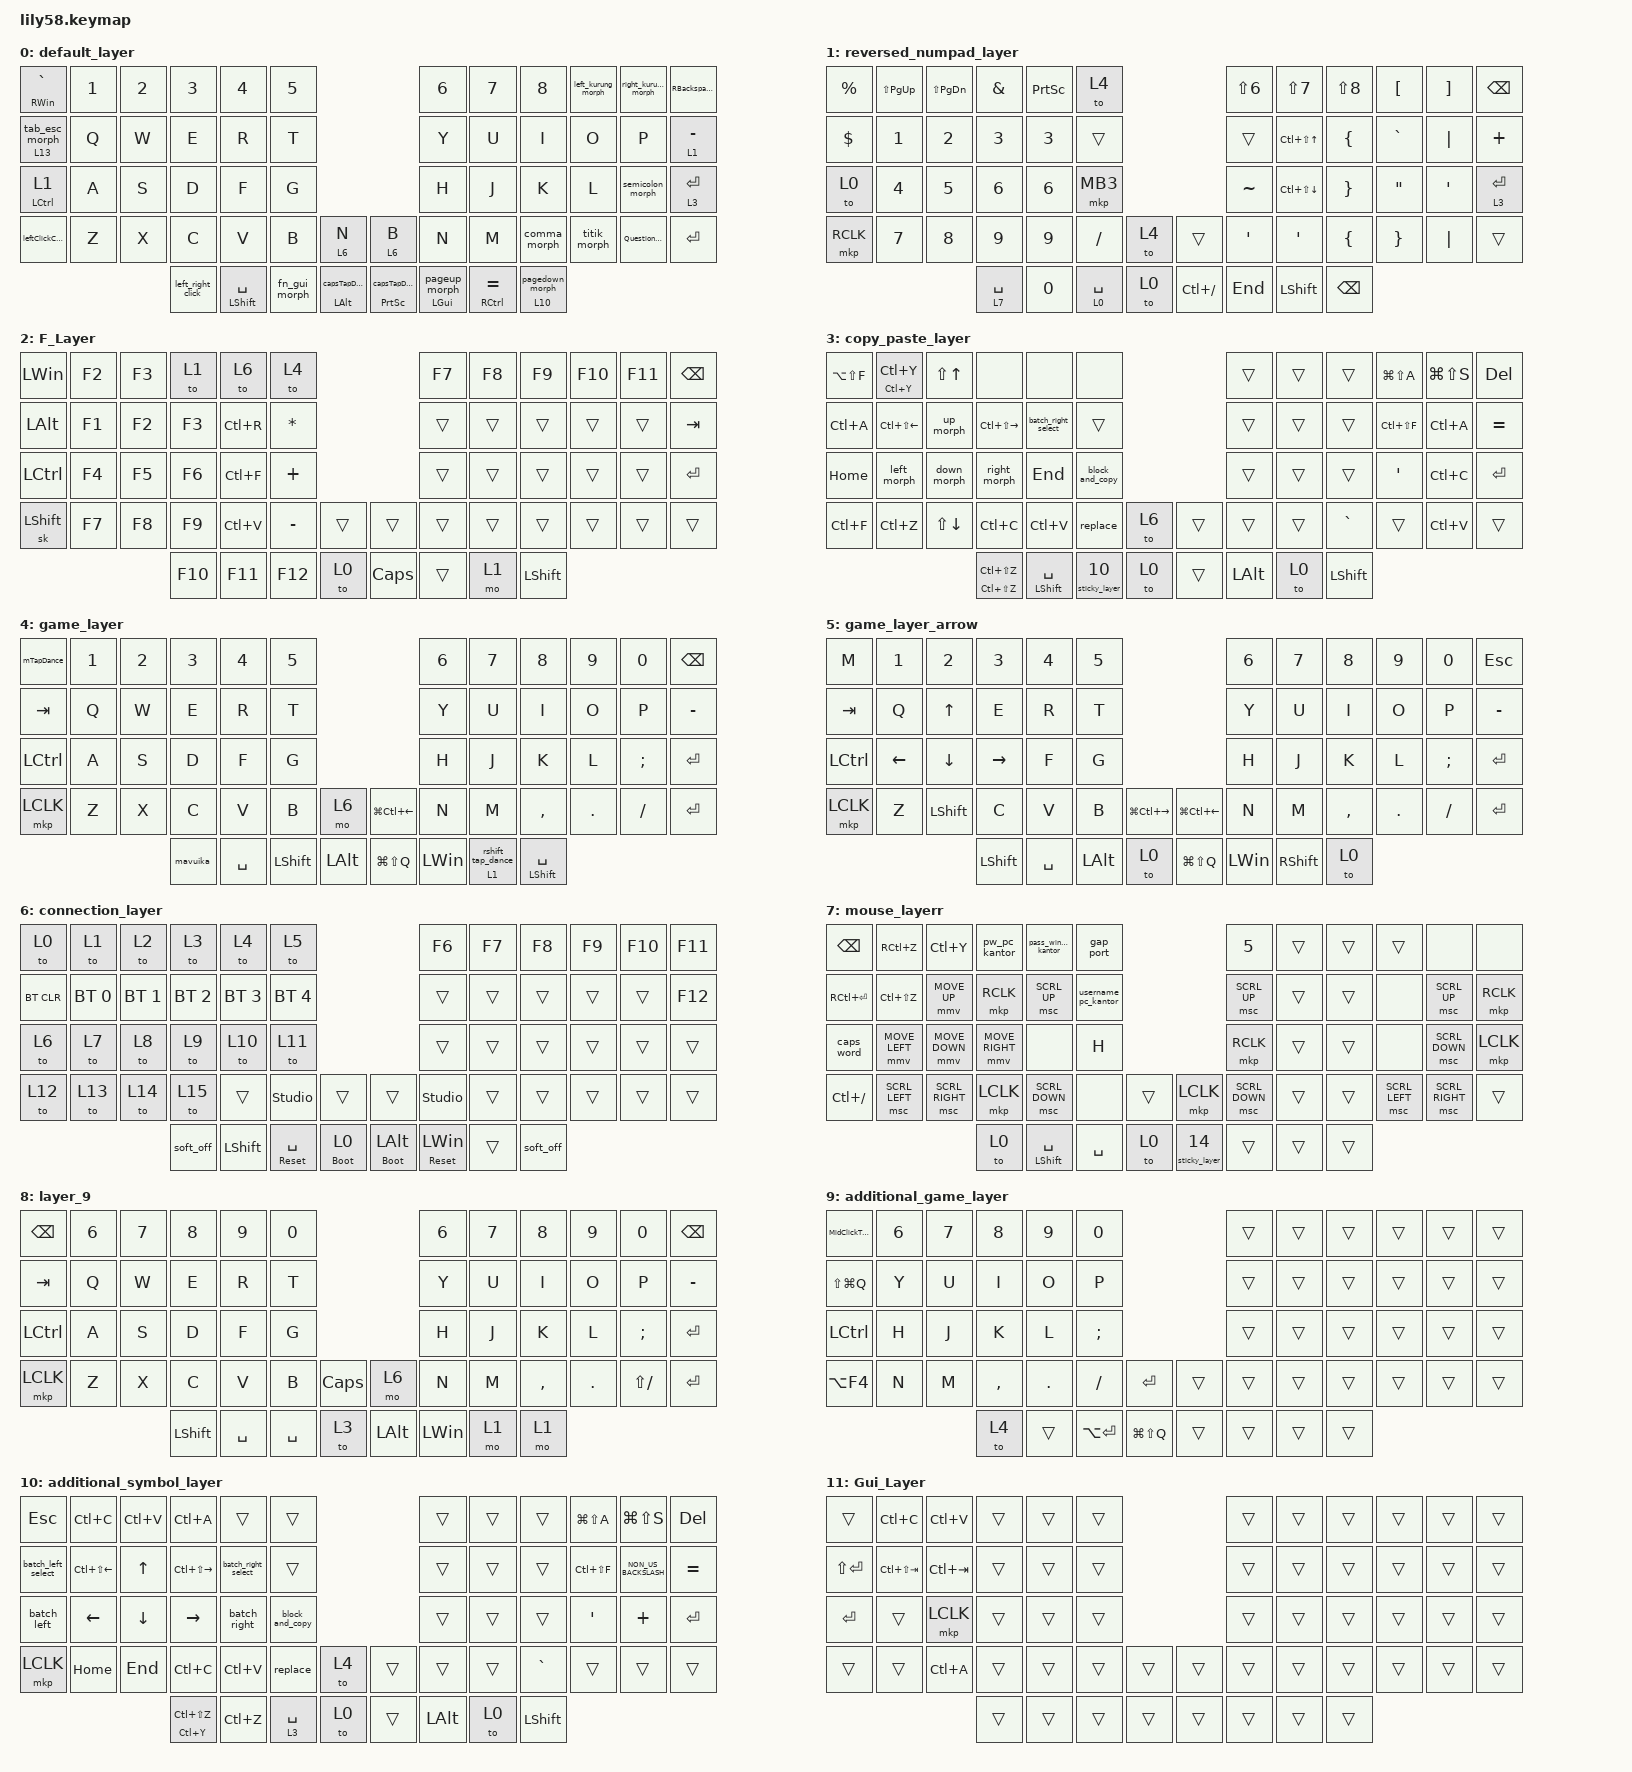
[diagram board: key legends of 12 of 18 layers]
/*
 * Copyright (c) 2020 The ZMK Contributors
 *
 * SPDX-License-Identifier: MIT
 */

#define SPLIT_USB_DETECT
#define ZMK_POINTING_DEFAULT_MOVE_VAL 1800  // default: 600
#define ZMK_POINTING_DEFAULT_SCRL_VAL 160    // default: 10

#include <dt-bindings/zmk/mouse.h>
#include <behaviors.dtsi>
#include <dt-bindings/zmk/bt.h>
#include <dt-bindings/zmk/keys.h>
#include <dt-bindings/zmk/pointing.h>

/ {
    combos {
        compatible = "zmk,combos";

        r_click {
            bindings = <&mkp RCLK>;
            key-positions = <37 25>;
            layers = <0>;
            timeout-ms = <1500>;
        };

        esc {
            bindings = <&kp ESCAPE>;
            key-positions = <13 37>;
            timeout-ms = <1500>;
            layers = <0>;
        };

        SPAM_W {
            bindings = <&kt W>;
            key-positions = <0 14>;
            layers = <4>;
        };

        win_game_mode {
            bindings = <&kp LEFT_WIN>;
            key-positions = <36 50>;
            layers = <5 4>;
        };

        click_copy {
            bindings = <&kp LC(C)>;
            key-positions = <50 14>;
            timeout-ms = <350>;
            layers = <0>;
        };

        click_paste {
            bindings = <&kp LC(V)>;
            key-positions = <50 27>;
            timeout-ms = <350>;
            layers = <0>;
        };

        click_select_all {
            bindings = <&kp LC(A)>;
            key-positions = <50 25>;
            timeout-ms = <350>;
            layers = <0>;
        };

        click_redo {
            bindings = <&kp LC(LS(Z))>;
            key-positions = <50 26>;
            layers = <0>;
            timeout-ms = <350>;
        };

        click_shift_enter {
            bindings = <&kp LS(ENTER)>;
            key-positions = <50 12>;
            layers = <0>;
            timeout-ms = <350>;
        };

        click_enter {
            bindings = <&kp ENTER>;
            key-positions = <50 39>;
            layers = <0>;
            timeout-ms = <350>;
        };

        click_ctrl_y {
            bindings = <&kp LC(Y)>;
            key-positions = <50 13>;
            timeout-ms = <350>;
            layers = <0>;
        };

        click_backspace {
            bindings = <&kp LC(BACKSPACE)>;
            key-positions = <50 0>;
            timeout-ms = <350>;
            layers = <0>;
        };

        click_delete {
            bindings = <&kp DELETE>;
            key-positions = <50 1>;
            layers = <0>;
            timeout-ms = <350>;
        };

        click_alt_tab {
            bindings = <&kp LA(TAB)>;
            key-positions = <50 38>;
            timeout-ms = <350>;
            layers = <0>;
        };

        click_undo {
            bindings = <&kp LC(Z)>;
            key-positions = <50 37>;
            timeout-ms = <350>;
            layers = <0>;
        };

        ctrl_delete {
            bindings = <&kp DELETE>;
            key-positions = <0 24>;
            timeout-ms = <350>;
            layers = <0>;
        };
    };

    macros {
        kurung: kurung {
            compatible = "zmk,behavior-macro";
            #binding-cells = <0>;
            bindings = <&kp LS(N9) &kp LS(N0)>;
            label = "KURUNG";
        };

        kurung2: kurung2 {
            compatible = "zmk,behavior-macro";
            #binding-cells = <0>;
            bindings = <&kp LS(LEFT_BRACKET) &kp LS(RIGHT_BRACKET)>;
            label = "KURUNG2";
        };

        kurung3: kurung3 {
            compatible = "zmk,behavior-macro";
            #binding-cells = <0>;
            bindings = <&kp LEFT_BRACKET &kp RIGHT_BRACKET>;
            label = "KURUNG3";
        };

        replace: replace {
            compatible = "zmk,behavior-macro";
            #binding-cells = <0>;
            bindings = <&mkp LCLK &mkp LCLK &kp LC(V)>;
            label = "REPLACE";
        };

        block_and_copy: block_and_copy {
            compatible = "zmk,behavior-macro";
            #binding-cells = <0>;
            bindings = <&mkp LCLK &mkp LCLK &kp LC(C)>;
            label = "BLOCK_AND_COPY";
        };

        sticky_shift_layer: sticky_shift_layer {
            compatible = "zmk,behavior-macro";
            #binding-cells = <0>;
            bindings = <&macro_tap>, <&none>;

            label = "STICKY_SHIFT_LAYER";
        };

        spam_f: spam_f {
            compatible = "zmk,behavior-macro";
            #binding-cells = <0>;
            bindings =
                <&kp F>,
                <&macro_wait_time 300>,
                <&kp F>,
                <&macro_wait_time 300>,
                <&kp F>,
                <&macro_wait_time 300>,
                <&kp F>,
                <&macro_wait_time 300>,
                <&kp F>,
                <&macro_wait_time 300>,
                <&kp F>,
                <&macro_wait_time 300>,
                <&kp F>,
                <&macro_wait_time 300>,
                <&kp F>,
                <&macro_wait_time 300>,
                <&kp F>,
                <&macro_wait_time 300>,
                <&kp F>,
                <&macro_wait_time 300>,
                <&kp F>,
                <&macro_wait_time 300>,
                <&kp F>,
                <&macro_wait_time 300>,
                <&kp F>,
                <&macro_wait_time 300>,
                <&kp F>,
                <&macro_wait_time 300>,
                <&kp F>,
                <&macro_wait_time 300>,
                <&kp F>,
                <&macro_wait_time 300>,
                <&kp F>;

            label = "SPAM_F";
        };

        username_pc_kantor: username_pc_kantor {
            compatible = "zmk,behavior-macro";
            #binding-cells = <0>;
            bindings = <&kp LS(A) &kp D &kp M &kp I &kp N &kp I &kp S &kp T &kp R &kp A &kp T &kp O &kp R>;
            label = "USERNAME_PC_KANTOR";
        };

        pw_pc_kantor: pw_pc_kantor {
            compatible = "zmk,behavior-macro";
            #binding-cells = <0>;
            bindings = <&none &kp G &kp N4 &kp P &kp DOT &kp LS(P) &kp N0 &kp N &kp C &kp N0 &kp LS(L) &kp AT &kp N1 &kp N3 &kp N7 &kp N4 &kp N0>;
            label = "PW_PC_KANTOR";
        };

        pass_windows_kantor: pass_windows_kantor {
            compatible = "zmk,behavior-macro";
            #binding-cells = <0>;
            bindings = <&none &kp LS(D) &kp N1 &kp LS(K) &kp N4 &kp DOT &kp N2 &kp N0 &kp N2 &kp N4>;
            label = "PASS_WINDOWS_KANTOR";
        };

        gap_port: gap_port {
            compatible = "zmk,behavior-macro";
            #binding-cells = <0>;
            bindings = <&none &kp G &kp A &kp P &kp P &kp R &kp I &kp N &kp T &kp AT &kp N2 &kp N0 &kp N2 &kp N1>;
            label = "GAP_PORT";
        };

        hold_scroll_up: hold_scroll_up {
            compatible = "zmk,behavior-macro";
            #binding-cells = <0>;
            bindings = <&macro_press>, <&msc SCRL_UP>;

            label = "HOLD_SCROLL_UP";
        };

        hold_scroll_down: hold_scroll_down {
            compatible = "zmk,behavior-macro";
            #binding-cells = <0>;
            bindings = <&macro_press>, <&msc SCRL_DOWN>;

            label = "HOLD_SCROLL_DOWN";
        };

        commaMacro: commaMacro {
            compatible = "zmk,behavior-macro";
            #binding-cells = <0>;
            bindings = <&macro_tap>, <&CommaTapDance>;

            label = "COMMAMACRO";
        };

        batch_left: batch_left {
            compatible = "zmk,behavior-macro";
            #binding-cells = <0>;
            bindings = <&kp LEFT_ARROW &kp LEFT_ARROW &kp LEFT_ARROW &kp LEFT_ARROW &kp LEFT_ARROW>;
            label = "BATCH_LEFT";
        };

        batch_right: batch_right {
            compatible = "zmk,behavior-macro";
            #binding-cells = <0>;
            bindings = <&kp RIGHT_ARROW &kp RIGHT_ARROW &kp RIGHT_ARROW &kp RIGHT_ARROW &kp RIGHT_ARROW>;
            label = "BATCH_RIGHT";
        };

        batch_right_select: batch_right_select {
            compatible = "zmk,behavior-macro";
            #binding-cells = <0>;
            bindings = <&kp LC(LS(RIGHT_ARROW)) &kp LC(LS(RIGHT_ARROW)) &kp LC(LS(RIGHT_ARROW)) &kp LC(LS(RIGHT_ARROW))>;
            label = "BATCH_RIGHT_SELECT";
        };

        batch_left_select: batch_left_select {
            compatible = "zmk,behavior-macro";
            #binding-cells = <0>;
            bindings = <&tapKp_holdSysReset 0 LC(LS(LEFT_ARROW)) &kp LS(LC(LEFT_ARROW)) &kp LC(LS(LEFT_ARROW)) &kp LC(LS(LEFT_ARROW))>;
            label = "BATCH_LEFT_SELECT";
        };

        MidMouseHold: MidMouseHold {
            compatible = "zmk,behavior-macro";
            #binding-cells = <0>;
            bindings = <&macro_press>, <&mkp MCLK>;

            label = "MIDMOUSEHOLD";
        };

        MidMouseRelease: MidMouseRelease {
            compatible = "zmk,behavior-macro";
            #binding-cells = <0>;
            bindings = <&macro_release>, <&mkp MCLK>;

            label = "MIDMOUSERELEASE";
        };

        Left_Scroll: Left_Scroll {
            compatible = "zmk,behavior-macro";
            #binding-cells = <0>;
            bindings = <&macro_press>, <&msc SCRL_LEFT>;

            label = "LEFT_SCROLL";
        };

        Right_Scroll: Right_Scroll {
            compatible = "zmk,behavior-macro";
            #binding-cells = <0>;
            bindings = <&macro_press>, <&msc SCRL_RIGHT>;

            label = "RIGHT_SCROLL";
        };

        repeat: spam_left_a {
            compatible = "zmk,behavior-macro";
            #binding-cells = <0>;
            bindings = <&macro_press>, <&key_repeat>;

            label = "SPAM_LEFT_A";
        };

        macro_alt_tab: macro_alt_tab {
            compatible = "zmk,behavior-macro";
            #binding-cells = <0>;
            bindings = <&macro_press>, <&kp LEFT_ALT>, <&macro_tap>, <&kp TAB>;

            label = "MACRO_ALT_TAB";
        };

        SPAM_W: SPAM_W {
            compatible = "zmk,behavior-macro";
            #binding-cells = <0>;
            bindings = <&none>, <&macro_press>;

            label = "SPAM_W";
        };

        enter_to_0: enter_to_0 {
            compatible = "zmk,behavior-macro";
            #binding-cells = <0>;
            bindings = <&kp ENTER &to 0>;
            label = "ENTER_TO_0";
        };

        mavuika: mavuika {
            compatible = "zmk,behavior-macro";
            #binding-cells = <0>;
            bindings =
                <&macro_press>,
                <&mkp LCLK>,
                <&macro_wait_time 200>,
                <&mkp RCLK>,
                <&macro_release>;

            label = "MAVUIKA";
        };
    };

    behaviors {
        mo_stickyKey: mo_stickyKey {
            compatible = "zmk,behavior-hold-tap";
            label = "MO_STICKYKEY";
            bindings = <&mo>, <&sk>;

            #binding-cells = <2>;
            tapping-term-ms = <150>;
        };

        short_layer_tap: short_layer_tap {
            compatible = "zmk,behavior-hold-tap";
            label = "SHORT_LAYER_TAP";
            bindings = <&mo>, <&kp>;

            #binding-cells = <2>;
            tapping-term-ms = <240>;
            flavor = "hold-preferred";
        };

        long_hold_tap: long_hold_tap {
            compatible = "zmk,behavior-hold-tap";
            label = "LONG_HOLD_TAP";
            bindings = <&kp>, <&kp>;

            #binding-cells = <2>;
            tapping-term-ms = <1000>;
            flavor = "tap-preferred";
        };

        space_shift: space_shift {
            compatible = "zmk,behavior-tap-dance";
            label = "SPACE_SHIFT";
            #binding-cells = <0>;
            bindings = <&kp SPACE>, <&sk LEFT_SHIFT>;

            tapping-term-ms = <250>;
        };

        mo_tap: mo_tap {
            compatible = "zmk,behavior-hold-tap";
            label = "MO_TAP";
            bindings = <&mo>, <&kp>;

            #binding-cells = <2>;
            tapping-term-ms = <240>;
        };

        to_mo: to_mo {
            compatible = "zmk,behavior-hold-tap";
            label = "TO_MO";
            bindings = <&mo>, <&to>;

            #binding-cells = <2>;
            tapping-term-ms = <235>;
        };

        hodlTo_tapKp: hodlTo_tapKp {
            compatible = "zmk,behavior-hold-tap";
            label = "HODLTO_TAPKP";
            bindings = <&kp>, <&to>;

            #binding-cells = <2>;
            tapping-term-ms = <300>;
        };

        custom_hold_tap: custom_hold_tap {
            compatible = "zmk,behavior-hold-tap";
            label = "CUSTOM_HOLD_TAP";
            bindings = <&kp>, <&kp>;

            #binding-cells = <2>;
            tapping-term-ms = <200>;
            flavor = "tap-preferred";
        };

        to_to: to_to {
            compatible = "zmk,behavior-hold-tap";
            label = "TO_TO";
            bindings = <&to>, <&to>;

            #binding-cells = <2>;
            flavor = "tap-preferred";
            tapping-term-ms = <300>;
        };

        rshift_tap_dance: rshift_tap_dance {
            compatible = "zmk,behavior-tap-dance";
            label = "RSHIFT_TAP_DANCE";
            #binding-cells = <0>;
            bindings = <&to 3>, <&to 6>, <&to 7>, <&to 4>;

            tapping-term-ms = <399>;
        };

        mo_with_tapdance: mo_with_tapdance {
            compatible = "zmk,behavior-hold-tap";
            label = "MO_WITH_TAPDANCE";
            bindings = <&mo>, <&rshift_tap_dance>;

            #binding-cells = <2>;
            tapping-term-ms = <400>;
        };

        stickyLayer_tap: stickyLayer_tap {
            compatible = "zmk,behavior-hold-tap";
            label = "STICKYLAYER_TAP";
            bindings = <&sl>, <&kp>;

            #binding-cells = <2>;
            tapping-term-ms = <240>;
        };

        tapKp_holdTo: tapKp_holdTo {
            compatible = "zmk,behavior-hold-tap";
            label = "TAPKP_HOLDTO";
            bindings = <&to>, <&kp>;

            #binding-cells = <2>;
            tapping-term-ms = <240>;
        };

        tapTo_holdBootloader: tapTo_holdBootloader {
            compatible = "zmk,behavior-hold-tap";
            label = "TAPTO_HOLDBOOTLOADER";
            bindings = <&bootloader>, <&to>;

            #binding-cells = <2>;
            tapping-term-ms = <240>;
        };

        tapKp_Bootloader: tapKp_Bootloader {
            compatible = "zmk,behavior-hold-tap";
            label = "TAPKP_BOOTLOADER";
            bindings = <&bootloader>, <&kp>;

            #binding-cells = <2>;
            tapping-term-ms = <240>;
        };

        tapKp_holdSysReset: tapKp_holdSysReset {
            compatible = "zmk,behavior-hold-tap";
            label = "TAPKP_HOLDSYSRESET";
            bindings = <&sys_reset>, <&kp>;

            #binding-cells = <2>;
            tapping-term-ms = <240>;
        };

        leftShiftTapDance: leftShiftTapDance {
            compatible = "zmk,behavior-tap-dance";
            label = "LEFTSHIFTTAPDANCE";
            #binding-cells = <0>;
            bindings = <&to 7>, <&to 1>;

            tapping-term-ms = <400>;
        };

        mo_leftShiftTapDance: mo_leftShiftTapDance {
            compatible = "zmk,behavior-hold-tap";
            label = "MO_LEFTSHIFTTAPDANCE";
            bindings = <&mo>, <&leftShiftTapDance>;

            #binding-cells = <2>;
            tapping-term-ms = <240>;
        };

        caps_enter_tapdance: caps_enter_tapdance {
            compatible = "zmk,behavior-tap-dance";
            label = "CAPS_ENTER_TAPDANCE";
            #binding-cells = <0>;
            tapping-term-ms = <400>;
            bindings = <&kp ENTER>, <&kp CAPS>;
        };

        layer_tap_dance: layer_tap_dance {
            compatible = "zmk,behavior-tap-dance";
            label = "LAYER_TAP_DANCE";
            #binding-cells = <0>;
            bindings = <&kp SPACE>, <&to 7>, <&to 3>, <&to 4>;

            tapping-term-ms = <350>;
        };

        layer_hold_tap_dance: layer_hold_tap_dance {
            compatible = "zmk,behavior-hold-tap";
            label = "LAYER_HOLD_TAP_DANCE";
            bindings = <&mo>, <&layer_tap_dance>;

            #binding-cells = <2>;
            tapping-term-ms = <400>;
            flavor = "tap-preferred";
        };

        shift_space_tap_dance: shift_space_tap_dance {
            compatible = "zmk,behavior-tap-dance";
            label = "SHIFT_SPACE_TAP_DANCE";
            #binding-cells = <0>;
            bindings = <&kp SPACE>, <&kp LEFT_SHIFT>;

            tapping-term-ms = <180>;
        };

        tapTo_HoldKp: tapTo_HoldKp {
            compatible = "zmk,behavior-hold-tap";
            label = "TAPTO_HOLDKP";
            bindings = <&kp>, <&to>;

            #binding-cells = <2>;
            tapping-term-ms = <240>;
        };

        holdMo_tapKp: holdMo_tapKp {
            compatible = "zmk,behavior-hold-tap";
            label = "HOLDMO_TAPKP";
            bindings = <&mo>, <&kp>;

            #binding-cells = <2>;
            tapping-term-ms = <240>;
        };

        wTapDance: wTapDance {
            compatible = "zmk,behavior-tap-dance";
            label = "WTAPDANCE";
            #binding-cells = <0>;
            bindings = <&kp W>, <&kp W>, <&kt W>;

            tapping-term-ms = <280>;
        };

        sTapDance: sTapDance {
            compatible = "zmk,behavior-tap-dance";
            label = "STAPDANCE";
            #binding-cells = <0>;
            tapping-term-ms = <280>;
            bindings = <&kp S>, <&kp S>, <&kt S>;
        };

        aTapDance: aTapDance {
            compatible = "zmk,behavior-tap-dance";
            label = "ATAPDANCE";
            #binding-cells = <0>;
            bindings = <&kp A>, <&kp A>, <&kt A>;

            tapping-term-ms = <280>;
        };

        dTapDance: dTapDance {
            compatible = "zmk,behavior-tap-dance";
            label = "DTAPDANCE";
            #binding-cells = <0>;
            bindings = <&kp D>, <&kp D>, <&kt D>;

            tapping-term-ms = <280>;
        };

        wHoldTapDance: wHoldTapDance {
            compatible = "zmk,behavior-hold-tap";
            label = "WHOLDTAPDANCE";
            bindings = <&kp>, <&wTapDance>;

            #binding-cells = <2>;
            tapping-term-ms = <210>;
        };

        sHoldTapDance: sHoldTapDance {
            compatible = "zmk,behavior-hold-tap";
            label = "SHOLDTAPDANCE";
            bindings = <&kp>, <&sTapDance>;

            #binding-cells = <2>;
            tapping-term-ms = <280>;
        };

        aHoldTapDance: aHoldTapDance {
            compatible = "zmk,behavior-hold-tap";
            label = "AHOLDTAPDANCE";
            bindings = <&kp>, <&aTapDance>;

            #binding-cells = <2>;
            tapping-term-ms = <150>;
        };

        dHoldTapDance: dHoldTapDance {
            compatible = "zmk,behavior-hold-tap";
            label = "DHOLDTAPDANCE";
            bindings = <&kp>, <&dTapDance>;

            #binding-cells = <2>;
            tapping-term-ms = <150>;
        };

        TapDance1: TapDance1 {
            compatible = "zmk,behavior-tap-dance";
            label = "TAPDANCE1";
            #binding-cells = <0>;
            bindings = <&kp NUMBER_1>, <&kp NUMBER_6>;

            tapping-term-ms = <300>;
        };

        TapDance2: TapDance2 {
            compatible = "zmk,behavior-tap-dance";
            label = "TAPDANCE2";
            #binding-cells = <0>;
            bindings = <&kp NUMBER_2>, <&kp N7>;

            tapping-term-ms = <300>;
        };

        TapDance3: TapDance3 {
            compatible = "zmk,behavior-tap-dance";
            label = "TAPDANCE3";
            #binding-cells = <0>;
            bindings = <&kp NUMBER_3>, <&kp N8>;

            tapping-term-ms = <300>;
        };

        TapDance4: TapDance4 {
            compatible = "zmk,behavior-tap-dance";
            label = "TAPDANCE4";
            #binding-cells = <0>;
            bindings = <&kp NUMBER_4>, <&kp N9>;

            tapping-term-ms = <300>;
        };

        TapDance5: TapDance5 {
            compatible = "zmk,behavior-tap-dance";
            label = "TAPDANCE5";
            #binding-cells = <0>;
            bindings = <&kp N5>, <&kp N0>;

            tapping-term-ms = <300>;
        };

        holdTapDance1: holdTapDance1 {
            compatible = "zmk,behavior-hold-tap";
            label = "HOLDTAPDANCE1";
            bindings = <&kp>, <&TapDance1>;

            #binding-cells = <2>;
            tapping-term-ms = <240>;
        };

        holdTapDance2: holdTapDance2 {
            compatible = "zmk,behavior-hold-tap";
            label = "HOLDTAPDANCE2";
            bindings = <&kp>, <&TapDance2>;

            #binding-cells = <2>;
            tapping-term-ms = <239>;
        };

        holdTapDance3: holdTapDance3 {
            compatible = "zmk,behavior-hold-tap";
            label = "HOLDTAPDANCE3";
            bindings = <&kp>, <&TapDance3>;

            #binding-cells = <2>;
            tapping-term-ms = <240>;
        };

        holdTapDance4: holdTapDance4 {
            compatible = "zmk,behavior-hold-tap";
            label = "HOLDTAPDANCE4";
            bindings = <&kp>, <&TapDance4>;

            #binding-cells = <2>;
            tapping-term-ms = <240>;
        };

        holdTapDance5: holdTapDance5 {
            compatible = "zmk,behavior-hold-tap";
            label = "HOLDTAPDANCE5";
            bindings = <&kp>, <&TapDance5>;

            #binding-cells = <2>;
            tapping-term-ms = <240>;
        };

        fTapDance: fTapDance {
            compatible = "zmk,behavior-tap-dance";
            label = "FTAPDANCE";
            #binding-cells = <0>;
            bindings = <&kp F>, <&spam_f>, <&kt F>;

            tapping-term-ms = <250>;
        };

        fHoldTapDance: fHoldTapDance {
            compatible = "zmk,behavior-hold-tap";
            label = "FHOLDTAPDANCE";
            bindings = <&kp>, <&fTapDance>;

            #binding-cells = <2>;
            tapping-term-ms = <199>;
        };

        mTapDance: mTapDance {
            compatible = "zmk,behavior-tap-dance";
            label = "MTAPDANCE";
            #binding-cells = <0>;
            bindings = <&kp ESCAPE>, <&kp M>, <&mkp MB3>;

            tapping-term-ms = <310>;
        };

        capsTapDance: capsTapDance {
            compatible = "zmk,behavior-tap-dance";
            label = "CAPSTAPDANCE";
            #binding-cells = <0>;
            bindings = <&kp LA(TAB)>, <&kp CLCK>;

            tapping-term-ms = <300>;
        };

        holdTapMsc: holdTapMsc {
            compatible = "zmk,behavior-hold-tap";
            label = "HOLDTAPMSC";
            bindings = <&msc>, <&msc>;

            #binding-cells = <2>;
            tapping-term-ms = <30>;
            quick-tap-ms = <300>;
        };

        holdCapsTapDance: holdCapsTapDance {
            compatible = "zmk,behavior-hold-tap";
            label = "HOLDCAPSTAPDANCE";
            bindings = <&kp>, <&capsTapDance>;

            #binding-cells = <2>;
            tapping-term-ms = <240>;
        };

        leftClickCommentOut: leftClickCommentOut {
            compatible = "zmk,behavior-mod-morph";
            label = "LEFTCLICKCOMMENTOUT";
            bindings = <&click_morph>, <&kp LC(SLASH)>;

            #binding-cells = <0>;
            mods = <(MOD_LCTL)>;
        };

        DasArrowMorph: DasArrowMorph {
            compatible = "zmk,behavior-mod-morph";
            label = "DASARROWMORPH";
            bindings = <&kp D>, <&kp RIGHT>;

            #binding-cells = <0>;
            mods = <(MOD_LGUI)>;
        };

        AasArrowMorph: AasArrowMorph {
            compatible = "zmk,behavior-mod-morph";
            label = "AASARROWMORPH";
            bindings = <&kp A>, <&kp LEFT_ARROW>;

            #binding-cells = <0>;
            mods = <(MOD_LGUI)>;
        };

        SasArrowMorph: SasArrowMorph {
            compatible = "zmk,behavior-mod-morph";
            label = "SASARROWMORPH";
            bindings = <&kp S>, <&kp DOWN_ARROW>;

            #binding-cells = <0>;
            mods = <(MOD_LGUI)>;
        };

        WasArrowMorph: WasArrowMorph {
            compatible = "zmk,behavior-mod-morph";
            label = "WASARROWMORPH";
            bindings = <&kp W>, <&kp UP_ARROW>;

            #binding-cells = <0>;
            mods = <(MOD_LGUI)>;
        };

        EasRBlockMorph: EasRBlockMorph {
            compatible = "zmk,behavior-mod-morph";
            label = "EASRBLOCKMORPH";
            bindings = <&kp E>, <&kp LC(LS(RIGHT_ARROW))>;

            #binding-cells = <0>;
            mods = <(MOD_LGUI)>;
        };

        QasLBlockMorph: QasLBlockMorph {
            compatible = "zmk,behavior-mod-morph";
            label = "QASLBLOCKMORPH";
            bindings = <&kp Q>, <&kp LC(LS(LEFT_ARROW))>;

            #binding-cells = <0>;
            mods = <(MOD_LGUI)>;
        };

        CasEndMorph: CasEndMorph {
            compatible = "zmk,behavior-mod-morph";
            label = "CASENDMORPH";
            bindings = <&kp C>, <&kp END>;

            #binding-cells = <0>;
            mods = <(MOD_LGUI)>;
        };

        XasEndMorph: XasEndMorph {
            compatible = "zmk,behavior-mod-morph";
            label = "XASENDMORPH";
            bindings = <&kp X>, <&kp HOME>;

            #binding-cells = <0>;
            mods = <(MOD_LGUI)>;
        };

        WinShiftQMorph: WinShiftQMorph {
            compatible = "zmk,behavior-mod-morph";
            label = "WINSHIFTQMORPH";
            bindings = <&long_mo_hold_tap 3 SPACE>, <&kp LG(LS(Q))>;

            #binding-cells = <0>;
            mods = <(MOD_LCTL)>;
        };

        RBackspaceMorph: RBackspaceMorph {
            compatible = "zmk,behavior-mod-morph";
            label = "RBACKSPACEMORPH";
            bindings = <&kp BACKSPACE>, <&kp LC(EQUAL)>;

            #binding-cells = <0>;
            mods = <(MOD_LCTL)>;
        };

        GraveTapDance: GraveTapDance {
            compatible = "zmk,behavior-tap-dance";
            label = "GRAVETAPDANCE";
            #binding-cells = <0>;
            bindings = <&kp LS(GRAVE)>, <&kp GRAVE>;

            tapping-term-ms = <300>;
        };

        LBackspaceMorph: LBackspaceMorph {
            compatible = "zmk,behavior-mod-morph";
            label = "LBACKSPACEMORPH";
            bindings = <&kp ESCAPE>, <&GraveTapDance>;

            #binding-cells = <0>;
            mods = <(MOD_RCTL|MOD_LCTL)>;
        };

        RBackspaceMorphFinal: RBackspaceMorphFinal {
            compatible = "zmk,behavior-mod-morph";
            label = "RBACKSPACEMORPHFINAL";
            bindings = <&kp BACKSPACE>, <&kp DELETE>;

            #binding-cells = <0>;
            mods = <(MOD_LCTL|MOD_RCTL)>;
        };

        CommaTapDance: CommaTapDance {
            compatible = "zmk,behavior-tap-dance";
            label = "COMMATAPDANCE";
            #binding-cells = <0>;
            bindings = <&kp COMMA>, <&kp LEFT_BRACKET>, <&kp LEFT_BRACE>;

            tapping-term-ms = <300>;
        };

        TitikTapDance: TitikTapDance {
            compatible = "zmk,behavior-tap-dance";
            label = "TITIKTAPDANCE";
            #binding-cells = <0>;
            bindings = <&kp PERIOD>, <&kp RIGHT_BRACKET>, <&kp RIGHT_BRACE>;

            tapping-term-ms = <300>;
        };

        QuestionMarkTapDance: QuestionMarkTapDance {
            compatible = "zmk,behavior-tap-dance";
            label = "QUESTIONMARKTAPDANCE";
            #binding-cells = <0>;
            bindings = <&kp SLASH>, <&kp QUESTION>;

            tapping-term-ms = <210>;
        };

        QuestionMarkHoldTap: QuestionMarkHoldTap {
            compatible = "zmk,behavior-hold-tap";
            label = "QUESTIONMARKHOLDTAP";
            bindings = <&kp>, <&QuestionMarkTapDance>;

            #binding-cells = <2>;
            tapping-term-ms = <240>;
            flavor = "tap-preferred";
        };

        MinusTapDance: MinusTapDance {
            compatible = "zmk,behavior-tap-dance";
            label = "MINUSTAPDANCE";
            #binding-cells = <0>;
            bindings = <&kp MINUS>, <&kp PIPE>, <&kp NON_US_BACKSLASH>;

            tapping-term-ms = <300>;
        };

        MinusHoldTap: MinusHoldTap {
            compatible = "zmk,behavior-hold-tap";
            label = "MINUSHOLDTAP";
            bindings = <&kp>, <&MinusTapDance>;

            #binding-cells = <2>;
            tapping-term-ms = <240>;
            flavor = "tap-preferred";
        };

        PetikTapDance: PetikTapDance {
            compatible = "zmk,behavior-tap-dance";
            label = "PETIKTAPDANCE";
            #binding-cells = <0>;
            bindings = <&kp SEMICOLON>, <&kp DOUBLE_QUOTES>, <&kp SQT>;

            tapping-term-ms = <300>;
        };

        MscUpTapDance: MscUpTapDance {
            compatible = "zmk,behavior-tap-dance";
            label = "MSCUPTAPDANCE";
            #binding-cells = <0>;
            bindings = <&msc MOVE_UP>, <&msc MOVE_UP>;

            tapping-term-ms = <300>;
        };

        MscDownTapDance: MscDownTapDance {
            compatible = "zmk,behavior-tap-dance";
            label = "MSCDOWNTAPDANCE";
            #binding-cells = <0>;
            bindings = <&msc MOVE_DOWN>, <&msc MOVE_DOWN>;

            tapping-term-ms = <300>;
        };

        EscDeleteTapDance: EscDeleteTapDance {
            compatible = "zmk,behavior-tap-dance";
            label = "ESCDELETETAPDANCE";
            #binding-cells = <0>;
            bindings = <&kp DELETE>, <&kp ESCAPE>;

            tapping-term-ms = <240>;
        };

        GlobalStickyKey: GlobalStickyKey {
            compatible = "zmk,behavior-sticky-key";
            label = "GLOBALSTICKYKEY";
            bindings = <&kp>;
            #binding-cells = <1>;
            release-after-ms = <300>;
        };

        CustomHoldTapSticky: CustomHoldTapSticky {
            compatible = "zmk,behavior-hold-tap";
            label = "CUSTOMHOLDTAPSTICKY";
            bindings = <&kp>, <&GlobalStickyKey>;

            #binding-cells = <2>;
            tapping-term-ms = <240>;
        };

        long_mo_hold_tap: long_mo_hold_tap {
            compatible = "zmk,behavior-hold-tap";
            label = "LONG_MO_HOLD_TAP";
            bindings = <&mo>, <&kp>;

            #binding-cells = <2>;
            tapping-term-ms = <600>;
        };

        semicolon_morph: semicolon_morph {
            compatible = "zmk,behavior-mod-morph";
            label = "SEMICOLON_MORPH";
            bindings = <&kp SEMICOLON>, <&kp SQT>;

            #binding-cells = <0>;
            mods = <(MOD_LCTL|MOD_RCTL)>;
        };

        comma_morph: comma_morph {
            compatible = "zmk,behavior-mod-morph";
            label = "COMMA_MORPH";
            bindings = <&kp COMMA>, <&kp DOLLAR>;

            #binding-cells = <0>;
            mods = <(MOD_LCTL|MOD_RCTL)>;
        };

        titik_morph: titik_morph {
            compatible = "zmk,behavior-mod-morph";
            label = "TITIK_MORPH";
            bindings = <&kp PERIOD>, <&kp HASH>;

            #binding-cells = <0>;
            mods = <(MOD_LCTL|MOD_RCTL)>;
        };

        minus_morph: minus_morph {
            compatible = "zmk,behavior-mod-morph";
            label = "MINUS_MORPH";
            bindings = <&kp MINUS>, <&kp EQUAL>;

            #binding-cells = <0>;
            mods = <(MOD_LCTL|MOD_RCTL)>;
        };

        new_behavior: new_behavior {
            compatible = "zmk,behavior-tap-dance";
            label = "NEW_BEHAVIOR";
            #binding-cells = <0>;
            bindings = <&kp A>, <&kp A>, <&kt A>;

            tapping-term-ms = <250>;
        };

        DoubleShiftTapDance: DoubleShiftTapDance {
            compatible = "zmk,behavior-tap-dance";
            label = "DOUBLESHIFTTAPDANCE";
            #binding-cells = <0>;
            bindings = <&kp LSHFT>, <&kt LSHFT>;

            tapping-term-ms = <250>;
        };

        DoubleShiftHoldTap: DoubleShiftHoldTap {
            compatible = "zmk,behavior-hold-tap";
            label = "DOUBLESHIFTHOLDTAP";
            bindings = <&kp>, <&DoubleShiftTapDance>;

            #binding-cells = <2>;
            tapping-term-ms = <250>;
        };

        MidClickTapDance: MidClickTapDance {
            compatible = "zmk,behavior-tap-dance";
            label = "MIDCLICKTAPDANCE";
            #binding-cells = <0>;
            bindings = <&MidMouseHold>, <&MidMouseRelease>;

            tapping-term-ms = <250>;
        };

        ScrollUpTapDance: ScrollUpTapDance {
            compatible = "zmk,behavior-tap-dance";
            label = "SCROLLUPTAPDANCE";
            #binding-cells = <0>;
            tapping-term-ms = <250>;
            bindings = <&msc MOVE_UP>, <&hold_scroll_up>;
        };

        ScrollUpHoldTap: ScrollUpHoldTap {
            compatible = "zmk,behavior-hold-tap";
            label = "SCROLLUPHOLDTAP";
            bindings = <&msc>, <&ScrollUpTapDance>;

            #binding-cells = <2>;
            tapping-term-ms = <250>;
        };

        ScrollDownTapDance: ScrollDownTapDance {
            compatible = "zmk,behavior-tap-dance";
            label = "SCROLLDOWNTAPDANCE";
            #binding-cells = <0>;
            tapping-term-ms = <250>;
            bindings = <&msc MOVE_DOWN>, <&hold_scroll_down>;
        };

        ScrollDownHoldTap: ScrollDownHoldTap {
            compatible = "zmk,behavior-hold-tap";
            label = "SCROLLDOWNHOLDTAP";
            bindings = <&msc>, <&ScrollDownTapDance>;

            #binding-cells = <2>;
            tapping-term-ms = <250>;
        };

        ScrollLeftTapDance: ScrollLeftTapDance {
            compatible = "zmk,behavior-tap-dance";
            label = "SCROLLLEFTTAPDANCE";
            #binding-cells = <0>;
            tapping-term-ms = <250>;
            bindings = <&msc MOVE_LEFT>, <&Left_Scroll>;
        };

        ScrollLeftHoldtTap: ScrollLeftHoldtTap {
            compatible = "zmk,behavior-hold-tap";
            label = "SCROLLLEFTHOLDTTAP";
            bindings = <&msc>, <&ScrollLeftTapDance>;

            #binding-cells = <2>;
            tapping-term-ms = <250>;
        };

        ScrollRightTapDance: ScrollRightTapDance {
            compatible = "zmk,behavior-tap-dance";
            label = "SCROLLRIGHTTAPDANCE";
            #binding-cells = <0>;
            tapping-term-ms = <250>;
            bindings = <&msc MOVE_RIGHT>, <&Right_Scroll>;
        };

        ScrollRightHoldTap: ScrollRightHoldTap {
            compatible = "zmk,behavior-hold-tap";
            label = "SCROLLRIGHTHOLDTAP";
            bindings = <&msc>, <&ScrollRightTapDance>;

            #binding-cells = <2>;
            tapping-term-ms = <250>;
        };

        TestMiddleClick: TestMiddleClick {
            compatible = "zmk,behavior-mouse-key-press";
            label = "TESTMIDDLECLICK";
            #binding-cells = <1>;
        };

        MiddleClickShift: MiddleClickShift {
            compatible = "zmk,behavior-mod-morph";
            label = "MIDDLECLICKSHIFT";
            bindings = <&kp ESC>, <&mkp MB3>;

            #binding-cells = <0>;
            mods = <(MOD_LSFT)>;
        };

        TapDanceLeftKurung: TapDanceLeftKurung {
            compatible = "zmk,behavior-tap-dance";
            label = "TAPDANCELEFTKURUNG";
            #binding-cells = <0>;
            bindings = <&kp N9>, <&kp LEFT_BRACKET>;

            tapping-term-ms = <250>;
        };

        HoldTapLeftKurung: HoldTapLeftKurung {
            compatible = "zmk,behavior-hold-tap";
            label = "HOLDTAPLEFTKURUNG";
            bindings = <&kp>, <&TapDanceLeftKurung>;

            #binding-cells = <2>;
            flavor = "tap-preferred";
            tapping-term-ms = <300>;
        };

        TapDanceRightKurung: TapDanceRightKurung {
            compatible = "zmk,behavior-tap-dance";
            label = "TAPDANCERIGHTKURUNG";
            #binding-cells = <0>;
            bindings = <&kp N0>, <&kp RIGHT_BRACKET>;

            tapping-term-ms = <250>;
        };

        HoldTapRightKurung: HoldTapRightKurung {
            compatible = "zmk,behavior-hold-tap";
            label = "HOLDTAPRIGHTKURUNG";
            bindings = <&kp>, <&TapDanceRightKurung>;

            #binding-cells = <2>;
            flavor = "tap-preferred";
            tapping-term-ms = <300>;
        };

        TapDancePetik: TapDancePetik {
            compatible = "zmk,behavior-tap-dance";
            label = "TAPDANCEPETIK";
            #binding-cells = <0>;
            tapping-term-ms = <300>;
            bindings = <&kp SQT>, <&kp LS(SQT)>;
        };

        AtauGarisTapDance: AtauGarisTapDance {
            compatible = "zmk,behavior-tap-dance";
            label = "ATAUGARISTAPDANCE";
            #binding-cells = <0>;
            tapping-term-ms = <300>;
            bindings = <&kp LS(NON_US_BACKSLASH)>, <&kp SLASH>;
        };

        QuestionMorph: QuestionMorph {
            compatible = "zmk,behavior-mod-morph";
            label = "QUESTIONMORPH";
            bindings = <&QuestionMarkTapDance>, <&kp NON_US_BACKSLASH>;

            #binding-cells = <0>;
            mods = <(MOD_LCTL|MOD_RCTL)>;
        };

        left_kurung_morph: left_kurung_morph {
            compatible = "zmk,behavior-mod-morph";
            label = "LEFT_KURUNG_MORPH";
            bindings = <&kp N9>, <&kp LEFT_BRACKET>;

            #binding-cells = <0>;
            mods = <(MOD_LCTL|MOD_RCTL)>;
        };

        right_kurung_morph: right_kurung_morph {
            compatible = "zmk,behavior-mod-morph";
            label = "RIGHT_KURUNG_MORPH";
            bindings = <&kp N0>, <&kp RIGHT_BRACKET>;

            #binding-cells = <0>;
            mods = <(MOD_LCTL|MOD_RCTL)>;
        };

        momentary_tap: momentary_tap {
            compatible = "zmk,behavior-hold-tap";
            label = "MOMENTARY_TAP";
            bindings = <&mo>, <&kp>;

            #binding-cells = <2>;
            tapping-term-ms = <500>;
        };

        sticky_layer: sticky_layer {
            compatible = "zmk,behavior-sticky-key";
            label = "STICKY_LAYER";
            bindings = <&mo>;
            #binding-cells = <1>;
            release-after-ms = <1000>;
        };

        esc_morph: esc_morph {
            compatible = "zmk,behavior-mod-morph";
            label = "ESC_MORPH";
            bindings = <&kp RGUI>, <&kp BACKSPACE>;

            #binding-cells = <0>;
            mods = <(MOD_LCTL)>;
        };

        custom_hold_esc_morph: custom_hold_esc_morph {
            compatible = "zmk,behavior-hold-tap";
            label = "CUSTOM_HOLD_ESC_MORPH";
            bindings = <&lgui_morph>, <&kp>;

            #binding-cells = <2>;
            tapping-term-ms = <300>;
        };

        pageup_morph: pageup_morph {
            compatible = "zmk,behavior-mod-morph";
            label = "PAGEUP_MORPH";
            bindings = <&kp LS(ENTER)>, <&kp PAGE_UP>;

            #binding-cells = <0>;
            mods = <(MOD_LCTL|MOD_RCTL)>;
        };

        pagedown_morph: pagedown_morph {
            compatible = "zmk,behavior-mod-morph";
            label = "PAGEDOWN_MORPH";
            bindings = <&kp HASH>, <&kp PAGE_DOWN>;

            #binding-cells = <0>;
            mods = <(MOD_LCTL|MOD_RCTL)>;
        };

        custom_hold_pageup_morph: custom_hold_pageup_morph {
            compatible = "zmk,behavior-hold-tap";
            label = "CUSTOM_HOLD_PAGEUP_MORPH";
            bindings = <&kp>, <&pageup_morph>;

            #binding-cells = <2>;
            tapping-term-ms = <398>;
        };

        custom_hold_pagedown_morph: custom_hold_pagedown_morph {
            compatible = "zmk,behavior-hold-tap";
            label = "CUSTOM_HOLD_PAGEDOWN_MORPH";
            bindings = <&mo>, <&pagedown_morph>;

            #binding-cells = <2>;
            tapping-term-ms = <400>;
        };

        custom_msc: custom_msc {
            compatible = "zmk,behavior-input-two-axis";
            label = "CUSTOM_MSC";
            #binding-cells = <1>;
            x-input-code = <20>;
            y-input-code = <20>;
            time-to-max-speed-ms = <300>;
            acceleration-exponent = <1>;
        };

        Left_Arrow_morph: Left_Arrow_morph {
            compatible = "zmk,behavior-mod-morph";
            label = "LEFT_ARROW_MORPH";
            bindings = <&kp LEFT_ARROW>, <&key_repeat>;

            #binding-cells = <0>;
            mods = <(MOD_LSFT|MOD_RSFT)>;
        };

        key_repeat_tap: key_repeat_tap {
            compatible = "zmk,behavior-hold-tap";
            label = "KEY_REPEAT_TAP";
            bindings = <&key_repeat>, <&kp>;

            #binding-cells = <2>;
            tapping-term-ms = <350>;
        };

        lrepeat_tap_dance: lrepeat_tap_dance {
            compatible = "zmk,behavior-tap-dance";
            label = "LREPEAT_TAP_DANCE";
            #binding-cells = <0>;
            bindings = <&kp LEFT_ARROW>, <&repeat>;

            tapping-term-ms = <250>;
        };

        brepeat_tap_dance: brepeat_tap_dance {
            compatible = "zmk,behavior-tap-dance";
            label = "BREPEAT_TAP_DANCE";
            #binding-cells = <0>;
            bindings = <&kp DOWN_ARROW>, <&repeat>;

            tapping-term-ms = <250>;
        };

        rrepeat_tap_dance: rrepeat_tap_dance {
            compatible = "zmk,behavior-tap-dance";
            label = "RREPEAT_TAP_DANCE";
            #binding-cells = <0>;
            bindings = <&kp RIGHT>, <&repeat>;

            tapping-term-ms = <250>;
        };

        urepeat_tap_dance: urepeat_tap_dance {
            compatible = "zmk,behavior-tap-dance";
            label = "UREPEAT_TAP_DANCE";
            #binding-cells = <0>;
            bindings = <&kp UP_ARROW>, <&repeat>;

            tapping-term-ms = <250>;
        };

        ctrl_enter_tap_dance: ctrl_enter_tap_dance {
            compatible = "zmk,behavior-tap-dance";
            label = "CTRL_ENTER_TAP_DANCE";
            #binding-cells = <0>;
            bindings = <&kp LEFT_CONTROL>, <&kp LC(ENTER)>;

            tapping-term-ms = <350>;
        };

        space_redo_mroph: space_redo_mroph {
            compatible = "zmk,behavior-mod-morph";
            label = "SPACE_REDO_MROPH";
            bindings = <&kp SPACE>, <&kp LC(LS(Z))>;

            #binding-cells = <0>;
            mods = <(MOD_LCTL)>;
        };

        mo8_redo_morph: mo8_redo_morph {
            compatible = "zmk,behavior-hold-tap";
            label = "MO8_REDO_MORPH";
            bindings = <&mo>, <&space_redo_mroph>;

            #binding-cells = <2>;
            tapping-term-ms = <300>;
        };

        esc_morp_tap_dance: esc_morp_tap_dance {
            compatible = "zmk,behavior-tap-dance";
            label = "ESC_MORP_TAP_DANCE";
            #binding-cells = <0>;
            bindings = <&esc_morph>, <&sk LS(LEFT_WIN)>, <&sk LEFT_GUI>;

            tapping-term-ms = <270>;
        };

        q_gui_num: q_gui_num {
            compatible = "zmk,behavior-mod-morph";
            label = "Q_GUI_NUM";
            bindings = <&kp Q>, <&kp RG(NUMBER_4)>;

            #binding-cells = <0>;
            mods = <(MOD_RGUI)>;
        };

        w_gui_num: w_gui_num {
            compatible = "zmk,behavior-mod-morph";
            label = "W_GUI_NUM";
            bindings = <&kp W>, <&kp RG(NUMBER_5)>;

            #binding-cells = <0>;
            mods = <(MOD_RGUI)>;
        };

        e_gui_num: e_gui_num {
            compatible = "zmk,behavior-mod-morph";
            label = "E_GUI_NUM";
            bindings = <&kp E>, <&kp RG(NUMBER_6)>;

            #binding-cells = <0>;
            mods = <(MOD_RGUI)>;
        };

        a_gui_num: a_gui_num {
            compatible = "zmk,behavior-mod-morph";
            label = "A_GUI_NUM";
            bindings = <&kp A>, <&kp RG(NUMBER_7)>;

            #binding-cells = <0>;
            mods = <(MOD_RGUI)>;
        };

        s_gui_num: s_gui_num {
            compatible = "zmk,behavior-mod-morph";
            label = "S_GUI_NUM";
            bindings = <&kp S>, <&kp RG(NUMBER_8)>;

            #binding-cells = <0>;
            mods = <(MOD_RGUI)>;
        };

        d_gui_num: d_gui_num {
            compatible = "zmk,behavior-mod-morph";
            label = "D_GUI_NUM";
            bindings = <&kp D>, <&kp RG(NUMBER_9)>;

            #binding-cells = <0>;
            mods = <(MOD_RGUI)>;
        };

        tab_esc_morph: tab_esc_morph {
            compatible = "zmk,behavior-mod-morph";
            label = "TAB_ESC_MORPH";
            bindings = <&tab_enter_tap_dance>, <&kp ESCAPE>;

            #binding-cells = <0>;
            mods = <(MOD_RGUI)>;
        };

        mo_tab_morph: mo_tab_morph {
            compatible = "zmk,behavior-hold-tap";
            label = "MO_TAB_MORPH";
            bindings = <&mo>, <&tab_esc_morph>;

            #binding-cells = <2>;
            tapping-term-ms = <299>;
        };

        click_morph: click_morph {
            compatible = "zmk,behavior-mod-morph";
            label = "CLICK_MORPH";
            bindings = <&mkp LCLK>, <&LeftClickCustomHoldTap 11 LC(V)>;

            #binding-cells = <0>;
            mods = <(MOD_RGUI)>;
        };

        ctrl_enter_morph: ctrl_enter_morph {
            compatible = "zmk,behavior-mod-morph";
            label = "CTRL_ENTER_MORPH";
            bindings = <&kp LCTRL>, <&kp LC(C)>;

            #binding-cells = <0>;
            mods = <(MOD_RGUI)>;
        };

        lgui_morph: lgui_morph {
            compatible = "zmk,behavior-mod-morph";
            label = "LGUI_MORPH";
            bindings = <&rgui_shift_grave_morph>, <&kp ESCAPE>;

            #binding-cells = <0>;
            mods = <(MOD_LCTL)>;
        };

        ctrl_tap_dance: ctrl_tap_dance {
            compatible = "zmk,behavior-tap-dance";
            label = "CTRL_TAP_DANCE";
            #binding-cells = <0>;
            bindings = <&ctrl_enter_morph>, <&kp LC(A)>, <&kp LC(V)>, <&sl 10>;

            tapping-term-ms = <280>;
        };

        c_gui_morph: c_gui_morph {
            compatible = "zmk,behavior-mod-morph";
            label = "C_GUI_MORPH";
            bindings = <&kp C>, <&kp LC(C)>;

            #binding-cells = <0>;
            mods = <(MOD_RGUI)>;
        };

        v_gui_morph: v_gui_morph {
            compatible = "zmk,behavior-mod-morph";
            label = "V_GUI_MORPH";
            bindings = <&kp V>, <&kp LC(V)>;

            #binding-cells = <0>;
            mods = <(MOD_RGUI)>;
        };

        z_gui_morph: z_gui_morph {
            compatible = "zmk,behavior-mod-morph";
            label = "Z_GUI_MORPH";
            bindings = <&kp Z>, <&kp LC(Z)>;

            #binding-cells = <0>;
            mods = <(MOD_RGUI)>;
        };

        fn_gui_morph: fn_gui_morph {
            compatible = "zmk,behavior-mod-morph";
            label = "FN_GUI_MORPH";
            bindings = <&mo8_redo_morph 7 0>, <&to 1>;

            #binding-cells = <0>;
            mods = <(MOD_LCTL)>;
        };

        tab_enter_tap_dance: tab_enter_tap_dance {
            compatible = "zmk,behavior-tap-dance";
            label = "TAB_ENTER_TAP_DANCE";
            #binding-cells = <0>;
            tapping-term-ms = <270>;
            bindings = <&kp TAB>, <&kp ENTER>;
        };

        left_morph: left_morph {
            compatible = "zmk,behavior-mod-morph";
            label = "LEFT_MORPH";
            bindings = <&kp LEFT_ARROW>, <&kp LC(LEFT_ARROW)>;

            #binding-cells = <0>;
            mods = <(MOD_LSFT)>;
        };

        right_morph: right_morph {
            compatible = "zmk,behavior-mod-morph";
            label = "RIGHT_MORPH";
            bindings = <&kp RIGHT>, <&kp LC(RIGHT)>;

            #binding-cells = <0>;
            mods = <(MOD_LSFT)>;
        };

        down_morph: down_morph {
            compatible = "zmk,behavior-mod-morph";
            label = "DOWN_MORPH";
            bindings = <&kp DOWN>, <&kp LC(DOWN_ARROW)>;

            #binding-cells = <0>;
            mods = <(MOD_LSFT)>;
        };

        up_morph: up_morph {
            compatible = "zmk,behavior-mod-morph";
            label = "UP_MORPH";
            bindings = <&kp UP_ARROW>, <&kp LC(UP_ARROW)>;

            #binding-cells = <0>;
            mods = <(MOD_LSFT)>;
        };

        rgui_shift_grave_morph: rgui_shift_grave_morph {
            compatible = "zmk,behavior-mod-morph";
            label = "RGUI_SHIFT_GRAVE_MORPH";
            bindings = <&mo 12>, <&kp LS(LEFT_WIN)>;

            #binding-cells = <0>;
            mods = <(MOD_LSFT)>;
        };

        CtrlTabMorph: CtrlTabMorph {
            compatible = "zmk,behavior-mod-morph";
            label = "CTRLTABMORPH";
            bindings = <&kp SPACE>, <&kp LC(TAB)>;

            #binding-cells = <0>;
            mods = <(MOD_RGUI)>;
        };

        CtrlTabHoldTap: CtrlTabHoldTap {
            compatible = "zmk,behavior-hold-tap";
            label = "CTRLTABHOLDTAP";
            bindings = <&kp>, <&CtrlTabMorph>;

            #binding-cells = <2>;
            tapping-term-ms = <350>;
        };

        GuiLayerShiftMorph: GuiLayerShiftMorph {
            compatible = "zmk,behavior-mod-morph";
            label = "GUILAYERSHIFTMORPH";
            bindings = <&kp LEFT_SHIFT>, <&mo 11>;

            #binding-cells = <0>;
            mods = <(MOD_RGUI)>;
        };

        GuiLayerShiftTap: GuiLayerShiftTap {
            compatible = "zmk,behavior-hold-tap";
            label = "GUILAYERSHIFTTAP";
            bindings = <&GuiLayerShiftMorph>, <&kp>;

            #binding-cells = <2>;
            tapping-term-ms = <350>;
        };

        LeftClickCustomHoldTap: LeftClickCustomHoldTap {
            compatible = "zmk,behavior-hold-tap";
            label = "LEFTCLICKCUSTOMHOLDTAP";
            bindings = <&mo>, <&kp>;

            #binding-cells = <2>;
            tapping-term-ms = <350>;
        };

        left_up_morph: left_up_morph {
            compatible = "zmk,behavior-mod-morph";
            label = "LEFT_UP_MORPH";
            bindings = <&kp LEFT>, <&kp UP_ARROW>;

            #binding-cells = <0>;
            mods = <(MOD_LSFT)>;
        };

        right_down_morph: right_down_morph {
            compatible = "zmk,behavior-mod-morph";
            label = "RIGHT_DOWN_MORPH";
            bindings = <&kp RIGHT>, <&kp DOWN>;

            #binding-cells = <0>;
            mods = <(MOD_LSFT)>;
        };

        enter_copy_morph: enter_copy_morph {
            compatible = "zmk,behavior-mod-morph";
            label = "ENTER_COPY_MORPH";
            bindings = <&kp ENTER>, <&kp LC(V)>;

            #binding-cells = <0>;
            mods = <(MOD_LSFT)>;
        };

        select_all_copy_morph: select_all_copy_morph {
            compatible = "zmk,behavior-mod-morph";
            label = "SELECT_ALL_COPY_MORPH";
            bindings = <&kp LC(A)>, <&kp LC(C)>;

            #binding-cells = <0>;
            mods = <(MOD_LSFT)>;
        };

        ctrl_and_ctrl_layer: ctrl_and_ctrl_layer {
            compatible = "zmk,behavior-hold-tap";
            label = "CTRL_AND_CTRL_LAYER";
            bindings = <&kp>, <&to>;

            #binding-cells = <2>;
            tapping-term-ms = <200>;
        };

        paste_left_click_morph: paste_left_click_morph {
            compatible = "zmk,behavior-mod-morph";
            label = "PASTE_LEFT_CLICK_MORPH";
            bindings = <&kp LS(ENTER)>, <&mkp LCLK>;

            #binding-cells = <0>;
            mods = <(MOD_LSFT)>;
        };

        left_right_click: left_right_click {
            compatible = "zmk,behavior-tap-dance";
            label = "LEFT_RIGHT_CLICK";
            #binding-cells = <0>;
            tapping-term-ms = <300>;
            bindings = <&mkp_hold_tap LCLK LCLK>, <&mkp RCLK>;
        };

        mkp_hold_tap: mkp_hold_tap {
            compatible = "zmk,behavior-hold-tap";
            label = "MKP_HOLD_TAP";
            bindings = <&mkp>, <&mkp>;

            #binding-cells = <2>;
            tapping-term-ms = <250>;
        };

        copy_paste_tap_dance: copy_paste_tap_dance {
            compatible = "zmk,behavior-tap-dance";
            label = "COPY_PASTE_TAP_DANCE";
            #binding-cells = <0>;
            bindings = <&kp LC(C)>, <&kp LC(V)>;

            tapping-term-ms = <250>;
        };

        select_all_prettier_tap_dance: select_all_prettier_tap_dance {
            compatible = "zmk,behavior-tap-dance";
            label = "SELECT_ALL_PRETTIER_TAP_DANCE";
            #binding-cells = <0>;
            bindings = <&kp LA(LS(F))>, <&kp LC(A)>;

            tapping-term-ms = <250>;
        };
    };

    keymap {
        compatible = "zmk,keymap";

        default_layer: default_layer {
            // ------------------------------------------------------------------------------------------------------------
            // |  ESC  |  1  |  2  |  3   |  4   |  5   |                   |  6   |  7    |  8    |  9   |   0   |   `   |
            // |  TAB  |  Q  |  W  |  E   |  R   |  T   |                   |  Y   |  U    |  I    |  O   |   P   |   -   |
            // |  CTRL |  A  |  S  |  D   |  F   |  G   |                   |  H   |  J    |  K    |  L   |   ;   |   '   |
            // | SHIFT |  Z  |  X  |  C   |  V   |  B   |   "["  |  |  "]"  |  N   |  M    |  ,    |  .   |   /   | SHIFT |
            //                     | ALT  | GUI  | LOWER|  ENTER |  | SPACE | RAISE| BSPC  | GUI   |

            bindings = <
&custom_hold_esc_morph RIGHT_WIN GRAVE  &kp N1  &kp N2  &kp N3             &kp N4                             &kp N5                                                                          &kp N6                                &kp N7                        &kp N8                            &left_kurung_morph  &right_kurung_morph  &RBackspaceMorphFinal
&mo_tab_morph 13 0                      &kp Q   &kp W   &kp E              &kp R                              &kp T                                                                           &kp Y                                 &kp U                         &kp I                             &kp O               &kp P                &short_layer_tap 1 MINUS
&ctrl_and_ctrl_layer LCTRL 1            &kp A   &kp S   &kp D              &kp F                              &kp G                                                                           &kp H                                 &kp J                         &kp K                             &kp L               &semicolon_morph     &short_layer_tap 3 ENTER
&leftClickCommentOut                    &kp Z   &kp X   &kp C              &kp V                              &kp B          &mo_tap 6 N                     &lt 6 B                          &kp N                                 &kp M                         &comma_morph                      &titik_morph        &QuestionMorph       &kp ENTER
                                                        &left_right_click  &custom_hold_tap LEFT_SHIFT SPACE  &fn_gui_morph  &holdCapsTapDance LEFT_ALT 0    &holdCapsTapDance PRINTSCREEN 0  &custom_hold_pageup_morph LEFT_GUI 0  &custom_hold_tap RCTRL EQUAL  &custom_hold_pagedown_morph 10 0
            >;

            sensor-bindings = <&inc_dec_kp C_VOL_UP C_VOL_DN>;
        };

        reversed_numpad_layer {
            bindings = <
&kp PERCENT  &kp LS(PAGE_UP)  &kp LS(PAGE_DOWN)  &kp AMPERSAND           &kp PRINTSCREEN  &to 4                                          &kp LS(NUMBER_6)  &kp LS(N7)            &kp LS(N8)       &kp LEFT_BRACKET   &kp RIGHT_BRACKET  &kp BACKSPACE
&kp DOLLAR   &kp NUMBER_1     &kp NUMBER_2       &kp NUMBER_3            &kp NUMBER_3     &trans                                         &trans            &kp LC(LS(UP_ARROW))  &kp LEFT_BRACE   &kp GRAVE          &kp PIPE           &kp PLUS
&to 0        &kp NUMBER_4     &kp NUMBER_5       &kp NUMBER_6            &kp NUMBER_6     &mkp MB3                                       &kp TILDE         &kp LC(LS(DOWN))      &kp RIGHT_BRACE  &kp DOUBLE_QUOTES  &kp SQT            &short_layer_tap 3 ENTER
&mkp RCLK    &kp N7           &kp N8             &kp N9                  &kp N9           &kp SLASH              &to 4    &trans         &kp SQT           &kp SQT               &kp LEFT_BRACE   &kp RIGHT_BRACE    &kp PIPE           &trans
                                                 &momentary_tap 7 SPACE  &kp N0           &tapKp_holdTo 0 SPACE  &to 0    &kp LC(SLASH)  &kp END           &kp LSHFT             &kp BACKSPACE
            >;
        };

        F_Layer {
            bindings = <
&kp LEFT_WIN    &kp F2  &kp F3  &to 1    &to 6      &to 4                                 &kp F7  &kp F8  &kp F9          &kp F10  &kp F11  &kp BACKSPACE
&kp LEFT_ALT    &kp F1  &kp F2  &kp F3   &kp LC(R)  &kp ASTERISK                          &trans  &trans  &trans          &trans   &trans   &kp TAB
&kp LCTRL       &kp F4  &kp F5  &kp F6   &kp LC(F)  &kp PLUS                              &trans  &trans  &trans          &trans   &trans   &kp ENTER
&sk LEFT_SHIFT  &kp F7  &kp F8  &kp F9   &kp LC(V)  &kp MINUS     &trans    &trans        &trans  &trans  &trans          &trans   &trans   &trans
                                &kp F10  &kp F11    &kp F12       &to 0     &kp CAPSLOCK  &trans  &mo 1   &kp LEFT_SHIFT
            >;
        };

        copy_paste_layer {
            bindings = <
&kp LA(LS(F))  &custom_hold_tap LC(Y) LC(Y)  &kp LS(UP_ARROW)    &none                                 &none                              &none                              &trans        &trans  &trans          &kp LG(LS(A))  &kp LG(LS(S))  &kp DEL
&kp LC(A)      &kp LC(LS(LEFT_ARROW))        &up_morph           &kp LC(LS(RIGHT))                     &batch_right_select                &trans                             &trans        &trans  &trans          &kp LC(LS(F))  &kp LC(A)      &kp EQUAL
&kp HOME       &left_morph                   &down_morph         &right_morph                          &kp END                            &block_and_copy                    &trans        &trans  &trans          &kp SQT        &kp LC(C)      &kp ENTER
&kp LC(F)      &kp LC(Z)                     &kp LS(DOWN_ARROW)  &kp LC(C)                             &kp LC(V)                          &replace          &to 6    &trans  &trans        &trans  &kp GRAVE       &trans         &kp LC(V)      &trans
                                                                 &custom_hold_tap LC(LS(Z)) LC(LS(Z))  &custom_hold_tap LEFT_SHIFT SPACE  &sticky_layer 10  &to 0    &trans  &kp LEFT_ALT  &to 0   &kp LEFT_SHIFT
            >;
        };

        game_layer {
            bindings = <
&mTapDance  &kp NUMBER_1  &kp N2  &kp N3    &kp N4     &kp N5                                                  &kp N6        &kp N7                 &kp N8                             &kp N9   &kp N0    &kp BACKSPACE
&kp TAB     &kp Q         &kp W   &kp E     &kp R      &kp T                                                   &kp Y         &kp U                  &kp I                              &kp O    &kp P     &kp MINUS
&kp LCTRL   &kp A         &kp S   &kp D     &kp F      &kp G                                                   &kp H         &kp J                  &kp K                              &kp L    &kp SEMI  &kp ENTER
&mkp LCLK   &kp Z         &kp X   &kp C     &kp V      &kp B           &mo 6           &kp LG(LC(LEFT_ARROW))  &kp N         &kp M                  &kp COMMA                          &kp DOT  &kp FSLH  &kp ENTER
                                  &mavuika  &kp SPACE  &kp LEFT_SHIFT  &kp LEFT_ALT    &kp LG(LS(Q))           &kp LEFT_WIN  &mo_with_tapdance 1 0  &custom_hold_tap LEFT_SHIFT SPACE
            >;

            sensor-bindings = <&inc_dec_kp C_VOL_UP C_VOL_DN>;
        };

        game_layer_arrow {
            bindings = <
&kp M      &kp N1          &kp N2          &kp N3     &kp N4     &kp N5                                                     &kp N6        &kp N7     &kp N8     &kp N9   &kp N0    &kp ESC
&kp TAB    &kp Q           &kp UP_ARROW    &kp E      &kp R      &kp T                                                      &kp Y         &kp U      &kp I      &kp O    &kp P     &kp MINUS
&kp LCTRL  &kp LEFT_ARROW  &kp DOWN_ARROW  &kp RIGHT  &kp F      &kp G                                                      &kp H         &kp J      &kp K      &kp L    &kp SEMI  &kp ENTER
&mkp LCLK  &kp Z           &kp LEFT_SHIFT  &kp C      &kp V      &kp B         &kp LG(LC(RIGHT))    &kp LG(LC(LEFT_ARROW))  &kp N         &kp M      &kp COMMA  &kp DOT  &kp FSLH  &kp ENTER
                                           &kp LSHFT  &kp SPACE  &kp LEFT_ALT  &to 0                &kp LG(LS(Q))           &kp LEFT_WIN  &kp RSHFT  &to 0
            >;

            sensor-bindings = <&inc_dec_kp C_VOL_UP C_VOL_DN>;
        };

        connection_layer {
            bindings = <
&to 0       &to 1         &to 2         &to 3         &to 4         &to 5                                                                                   &kp F6                          &kp F7  &kp F8     &kp F9  &kp F10  &kp F11
&bt BT_CLR  &bt BT_SEL 0  &bt BT_SEL 1  &bt BT_SEL 2  &bt BT_SEL 3  &bt BT_SEL 4                                                                            &trans                          &trans  &trans     &trans  &trans   &kp F12
&to 6       &to 7         &to 8         &to 9         &to 10        &to 11                                                                                  &trans                          &trans  &trans     &trans  &trans   &trans
&to 12      &to 13        &to 14        &to 15        &trans        &studio_unlock               &trans                       &trans                        &studio_unlock                  &trans  &trans     &trans  &trans   &trans
                                        &soft_off     &kp LSHFT     &tapKp_holdSysReset 0 SPACE  &tapTo_holdBootloader 0 0    &tapKp_Bootloader 0 LEFT_ALT  &tapKp_holdSysReset 0 LEFT_WIN  &trans  &soft_off
            >;
        };

        mouse_layerr {
            bindings = <
&kp BACKSPACE  &kp RC(Z)       &kp LC(Y)        &pw_pc_kantor    &pass_windows_kantor               &gap_port                                        &kp N5          &trans  &trans  &trans          &none            &none
&kp RC(ENTER)  &kp LC(LS(Z))   &mmv MOVE_UP     &mkp RCLK        &msc SCRL_UP                       &username_pc_kantor                              &msc SCRL_UP    &trans  &trans  &none           &msc SCRL_UP     &mkp RCLK
&caps_word     &mmv MOVE_LEFT  &mmv MOVE_DOWN   &mmv MOVE_RIGHT  &none                              &kp H                                            &mkp RCLK       &trans  &trans  &none           &msc SCRL_DOWN   &mkp LCLK
&kp LC(SLASH)  &msc SCRL_LEFT  &msc SCRL_RIGHT  &mkp LCLK        &msc SCRL_DOWN                     &none                &trans    &mkp LCLK         &msc SCRL_DOWN  &trans  &trans  &msc SCRL_LEFT  &msc SCRL_RIGHT  &trans
                                                &to 0            &custom_hold_tap LEFT_SHIFT SPACE  &kp SPACE            &to 0     &sticky_layer 14  &trans          &trans  &trans
            >;
        };

        layer_9 {
            bindings = <
&kp BACKSPACE  &kp N6  &kp N7  &kp N8     &kp N9     &kp N0                               &kp N6        &kp N7  &kp N8     &kp N9   &kp N0        &kp BACKSPACE
&kp TAB        &kp Q   &kp W   &kp E      &kp R      &kp T                                &kp Y         &kp U   &kp I      &kp O    &kp P         &kp MINUS
&kp LCTRL      &kp A   &kp S   &kp D      &kp F      &kp G                                &kp H         &kp J   &kp K      &kp L    &kp SEMI      &kp ENTER
&mkp LCLK      &kp Z   &kp X   &kp C      &kp V      &kp B      &kp CAPS    &mo 6         &kp N         &kp M   &kp COMMA  &kp DOT  &kp LS(FSLH)  &kp ENTER
                               &kp LSHFT  &kp SPACE  &kp SPACE  &to 3       &kp LEFT_ALT  &kp LEFT_WIN  &mo 1   &mo 1
            >;

            sensor-bindings = <&inc_dec_kp C_VOL_UP C_VOL_DN>;
        };

        additional_game_layer {
            bindings = <
&MidClickTapDance  &kp NUMBER_6  &kp N7  &kp N8     &kp N9      &kp N0                                  &trans  &trans  &trans  &trans  &trans  &trans
&kp LS(LG(Q))      &kp Y         &kp U   &kp I      &kp O       &kp P                                   &trans  &trans  &trans  &trans  &trans  &trans
&kp LCTRL          &kp H         &kp J   &kp K      &kp L       &kp SEMICOLON                           &trans  &trans  &trans  &trans  &trans  &trans
&kp LA(F4)         &kp N         &kp M   &kp COMMA  &kp PERIOD  &kp SLASH      &kp ENTER        &trans  &trans  &trans  &trans  &trans  &trans  &trans
                                         &to 4      &trans      &kp LA(ENTER)  &kp LG(LS(Q))    &trans  &trans  &trans  &trans
            >;
        };

        additional_symbol_layer {
            bindings = <
&kp ESCAPE          &kp LC(C)               &kp LC(V)     &kp LC(A)                         &trans               &trans                            &trans        &trans  &trans          &kp LG(LS(A))  &kp LG(LS(S))         &kp DEL
&batch_left_select  &kp LC(LS(LEFT_ARROW))  &kp UP_ARROW  &kp LC(LS(RIGHT))                 &batch_right_select  &trans                            &trans        &trans  &trans          &kp LC(LS(F))  &kp NON_US_BACKSLASH  &kp EQUAL
&batch_left         &kp LEFT_ARROW          &kp DOWN      &kp RIGHT                         &batch_right         &block_and_copy                   &trans        &trans  &trans          &kp SQT        &kp PLUS              &kp ENTER
&mkp LCLK           &kp HOME                &kp END       &kp LC(C)                         &kp LC(V)            &replace         &to 4    &trans  &trans        &trans  &kp GRAVE       &trans         &trans                &trans
                                                          &custom_hold_tap LC(Y) LC(LS(Z))  &kp LC(Z)            &mo_tap 3 SPACE  &to 0    &trans  &kp LEFT_ALT  &to 0   &kp LEFT_SHIFT
            >;
        };

        Gui_Layer {
            bindings = <
&trans         &kp LC(C)        &kp LC(V)    &trans  &trans  &trans                    &trans  &trans  &trans  &trans  &trans  &trans
&kp LS(ENTER)  &kp LC(LS(TAB))  &kp LC(TAB)  &trans  &trans  &trans                    &trans  &trans  &trans  &trans  &trans  &trans
&kp ENTER      &trans           &mkp LCLK    &trans  &trans  &trans                    &trans  &trans  &trans  &trans  &trans  &trans
&trans         &trans           &kp LC(A)    &trans  &trans  &trans  &trans    &trans  &trans  &trans  &trans  &trans  &trans  &trans
                                             &trans  &trans  &trans  &trans    &trans  &trans  &trans  &trans
            >;
        };

        L_GUI_MORPH {
            bindings = <
&trans         &kp LG(NUMBER_1)  &kp LG(NUMBER_2)  &kp LG(NUMBER_3)  &trans     &trans                    &trans  &trans  &trans  &trans  &trans  &trans
&kp LS(ENTER)  &kp LG(NUMBER_4)  &kp LG(N5)        &kp LG(NUMBER_6)  &trans     &trans                    &trans  &trans  &trans  &trans  &trans  &trans
&kp LC(C)      &kp LG(N7)        &kp LG(N8)        &kp LG(N9)        &trans     &trans                    &trans  &trans  &trans  &trans  &trans  &trans
&kp RC(A)      &kp LC(C)         &kp ENTER         &none             &none      &trans  &trans    &trans  &trans  &trans  &trans  &trans  &trans  &trans
                                                   &kp LC(V)         &kp LC(Y)  &trans  &trans    &trans  &trans  &trans  &trans
            >;
        };

        tab_layer {
            bindings = <
&select_all_prettier_tap_dance  &kp LC(C)              &kp LC(V)  &trans  &trans  &trans                    &trans  &trans  &trans  &trans  &trans  &trans
&trans                          &kp LC(A)              &trans     &trans  &trans  &trans                    &trans  &trans  &trans  &trans  &trans  &trans
&kp ENTER                       &trans                 &trans     &trans  &trans  &trans                    &trans  &trans  &trans  &trans  &trans  &trans
&kp LS(ENTER)                   &copy_paste_tap_dance  &trans     &trans  &trans  &trans  &trans    &trans  &trans  &trans  &trans  &trans  &trans  &trans
                                                                  &trans  &trans  &trans  &trans    &trans  &trans  &trans  &trans
            >;
        };

        ctrl_layer {
            bindings = <
&kp DELETE        &kp LC(Y)       &enter_copy_morph  &trans         &trans  &trans                    &trans  &trans  &trans  &trans  &trans  &trans
&sk LS(LEFT_WIN)  &sk LEFT_WIN    &kp ENTER          &trans         &trans  &trans                    &trans  &trans  &trans  &trans  &trans  &trans
&to 0             &left_up_morph  &right_down_morph  &trans         &trans  &trans                    &trans  &trans  &trans  &trans  &trans  &trans
&mkp LCLK         &kp LC(Z)       &kp LC(A)          &trans         &trans  &trans  &trans    &trans  &trans  &trans  &trans  &trans  &trans  &trans
                                                     &kp LC(LS(Z))  &trans  &trans  &to 0     &trans  &trans  &trans  &trans
            >;
        };

        raise_layer {
            // ------------------------------------------------------------------------------------------------------------
            // |       |     |     |      |      |      |                   |      |       |       |      |       |       |
            // |   `   |  1  |  2  |  3   |  4   |  5   |                   |  6   |   7   |   8   |  9   |   0   |       |
            // |   F1  |  F2 |  F3 |  F4  |  F5  |  F6  |                   |      |   <-  |   v   |  ^   |  ->   |       |
            // |   F7  |  F8 |  F9 |  F10 |  F11 |  F12 |        |  |       |  +   |   -   |   =   |  [   |   ]   |   \   |
            //                     |      |      |      |        |  |       |      |       |       |

            bindings = <
&trans     &kp F1  &kp F2  &kp F3   &kp F4    &kp F5                     &trans       &trans     &trans     &trans    &trans     &trans
&kp GRAVE  &kp F6  &kp F7  &kp F8   &kp F9    &kp F10                    &kp N6       &kp N7     &kp N8     &kp N9    &kp N0     &trans
&kp F1     &kp F2  &kp F3  &kp F4   &kp PLUS  &kp F11                    &trans       &kp LEFT   &kp DOWN   &kp UP    &kp RIGHT  &trans
&kp F7     &kp F8  &kp F9  &kp F10  &kp F11   &kp F12  &trans    &trans  &kp KP_PLUS  &kp MINUS  &kp EQUAL  &kp LBKT  &kp RBKT   &kp BSLH
                           &trans   &trans    &trans   &trans    &trans  &trans       &trans     &trans
            >;

            sensor-bindings = <&inc_dec_kp C_VOL_UP C_VOL_DN>;
        };

        lower_layer {
            // ------------------------------------------------------------------------------------------------------------
            // | BTCLR | BT1 | BT2 |  BT3 |  BT4 |  BT5 |                   |      |       |       |      |       |       |
            // |  F1   |  F2 |  F3 |  F4  |  F5  |  F6  |                   |  F7  |  F8   |  F9   |  F10 |  F11  |  F12  |
            // |   `   |  !  |  @  |  #   |  $   |  %   |                   |  ^   |  &    |  *    |  (   |   )   |   ~   |
            // |       |     |     |      |      |      |        |  |       |      |  _    |  +    |  {   |   }   |  "|"  |
            //                     |      |      |      |        |  |       |      |       |       |

            bindings = <
&bt BT_CLR  &bt BT_SEL 0  &bt BT_SEL 1  &bt BT_SEL 2  &bt BT_SEL 3  &bt BT_SEL 4                    &trans     &trans     &trans           &trans    &trans    &trans
&kp F1      &kp F2        &kp F3        &kp F4        &kp F5        &kp F6                          &kp F7     &kp F8     &kp F9           &kp F10   &kp F11   &kp F12
&kp GRAVE   &kp EXCL      &kp AT        &kp HASH      &kp DOLLAR    &kp PRCNT                       &kp CARET  &kp AMPS   &kp KP_MULTIPLY  &kp LPAR  &kp RPAR  &kp TILDE
&trans      &trans        &trans        &trans        &trans        &trans        &trans    &trans  &trans     &kp MINUS  &kp KP_PLUS      &kp LBRC  &kp RBRC  &kp PIPE
                                        &trans        &trans        &trans        &trans    &trans  &trans     &trans     &trans
            >;

            sensor-bindings = <&inc_dec_kp C_VOL_UP C_VOL_DN>;
        };

        sticky_ctrl {
            bindings = <
&kp DELETE  &trans     &trans     &trans     &trans          &trans                       &trans  &trans  &trans  &trans  &trans  &trans
&trans      &trans     &trans     &trans     &kp LC(R)       &trans                       &trans  &trans  &trans  &trans  &trans  &trans
&trans      &kp LC(A)  &kp LC(S)  &trans     &kp LC(F)       &trans                       &trans  &trans  &trans  &trans  &trans  &trans
&trans      &kp LC(Z)  &kp LC(X)  &kp LC(C)  &kp LC(V)       &kp LC(B)  &trans    &trans  &trans  &trans  &trans  &trans  &trans  &trans
                                  &trans     &kp LEFT_SHIFT  &trans     &to 0     &trans  &trans  &trans  &trans
            >;
        };
    };
};
